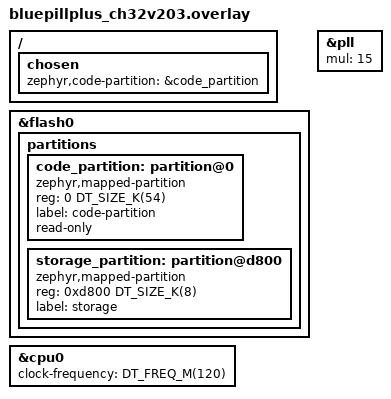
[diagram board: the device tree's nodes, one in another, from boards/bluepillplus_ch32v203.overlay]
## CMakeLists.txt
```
# SPDX-License-Identifier: Apache-2.0

cmake_minimum_required(VERSION 3.28.0)
find_package(Zephyr REQUIRED HINTS $ENV{ZEPHYR_BASE})
project(flash_shell)

FILE(GLOB app_sources src/*.c)
target_sources(app PRIVATE ${app_sources})
```

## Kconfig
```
# Copyright (c) 2020, Linaro Ltd.
# SPDX-License-Identifier: Apache-2.0

source "Kconfig.zephyr"

if ARM_MPU
config MPU_ALLOW_FLASH_WRITE
	def_bool y
endif
```

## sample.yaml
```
sample:
  description: Shell commands for inspecting flash driver behavior
  name: Flash shell
tests:
  sample.drivers.flash.shell:
    tags:
      - flash
      - shell
    filter: CONFIG_FLASH_HAS_DRIVER_ENABLED and dt_chosen_enabled('zephyr,flash-controller')
            and not CONFIG_SOC_SERIES_BSIM_NRFXX
    platform_exclude:
      - stm32h7s78_dk
      - gd32f350r_eval
      - lp_em_cc2340r5moda
    harness: shell
    extra_configs:
      - arch:posix:CONFIG_UART_NATIVE_PTY_0_ON_STDINOUT=y
    min_ram: 12
    integration_platforms:
      - qemu_x86
      - native_sim
```

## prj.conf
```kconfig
CONFIG_PRINTK=y
CONFIG_SHELL=y
CONFIG_LOG=y
CONFIG_FLASH=y
CONFIG_FLASH_SHELL=y
CONFIG_FLASH_SHELL_TEST_COMMANDS=y
CONFIG_FLASH_STM32WBA_BYTE_WRITE_EMULATION=n
```

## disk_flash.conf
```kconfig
# RAM-Disk config
CONFIG_DISK_ACCESS=y
CONFIG_DISK_DRIVERS=y
CONFIG_DISK_DRIVER_RAM=y

# Initialize flash_disk after ramdisk
CONFIG_FLASH_INIT_PRIORITY=51
```

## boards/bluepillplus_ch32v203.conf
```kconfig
CONFIG_USE_DT_CODE_PARTITION=y

# Shrink the defaults to fit within the 52 KiB of flash and 20 KiB of RAM.
CONFIG_FLASH_SHELL_TEST_COMMANDS=n
CONFIG_KERNEL_SHELL=n
CONFIG_DATE_SHELL=n
CONFIG_LOG_MODE_MINIMAL=y
```

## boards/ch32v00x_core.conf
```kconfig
CONFIG_USE_DT_CODE_PARTITION=y

# Shrink the defaults to fit within the 52 KiB of flash and 8 KiB of RAM.
CONFIG_FLASH_SHELL_TEST_COMMANDS=n
CONFIG_FLASH_SHELL_BUFFER_SIZE=0x400
CONFIG_MAIN_STACK_SIZE=440
CONFIG_ISR_STACK_SIZE=256
CONFIG_LOG_MODE_MINIMAL=y
CONFIG_KERNEL_SHELL=n
CONFIG_DATE_SHELL=n
```

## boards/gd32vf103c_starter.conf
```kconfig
# This board only has 32KB SRAM, can not afford 16 KB memory pool, use 8KB instead.
CONFIG_HEAP_MEM_POOL_SIZE=8192
```

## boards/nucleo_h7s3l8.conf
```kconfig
# Copyright (c) 2026 EXALT Technologies
# SPDX-License-Identifier: Apache-2.0

CONFIG_MSPI=y
CONFIG_LOG=n
CONFIG_HEAP_MEM_POOL_SIZE=8192
CONFIG_CACHE_MANAGEMENT=n
CONFIG_SHELL_MINIMAL=y
CONFIG_SIZE_OPTIMIZATIONS=y
```

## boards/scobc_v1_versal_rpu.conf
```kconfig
# SPDX-License-Identifier: Apache-2.0

CONFIG_XIP=n

# Keep the vector table at 0x00000000 (TCM)
CONFIG_ROMSTART_RELOCATION_ROM=y
CONFIG_ROMSTART_REGION_ADDRESS=0x00000000
CONFIG_ROMSTART_REGION_SIZE=1
```

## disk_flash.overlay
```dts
/*
 * Copyright (c) 2023 Endress+Hauser AG
 *
 * SPDX-License-Identifier: Apache-2.0
 */

/ {
	ramdisk0 {
		compatible = "zephyr,ram-disk";
		disk-name = "DISK0";
		sector-size = <512>;
		sector-count = <2>;
	};

	disk_flash: disk_flash {
		compatible = "zephyr,disk-flash";
		status = "okay";
		size = <4096>;
		page-size = <1024>;
		disk-name = "DISK0";
		disk-sector-size = <512>;
		disk-offset = <512>;
	};
};
```

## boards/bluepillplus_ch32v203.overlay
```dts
/*
 * SPDX-FileCopyrightText: Copyright Michael Hope <michaelh@juju.nz>
 *
 * SPDX-License-Identifier: Apache-2.0
 */

/ {
	chosen {
		zephyr,code-partition = &code_partition;
	};
};

&flash0 {
	partitions {
		ranges;
		#address-cells = <1>;
		#size-cells = <1>;

		code_partition: partition@0 {
			compatible = "zephyr,mapped-partition";
			reg = <0 DT_SIZE_K(54)>;
			label = "code-partition";
			read-only;
		};

		storage_partition: partition@d800 {
			compatible = "zephyr,mapped-partition";
			reg = <0xd800 DT_SIZE_K(8)>;
			label = "storage";
		};
	};
};

/*
 * Section 32.1 note 2 says "it is strongly recommended that the system
 * main frequency is not greater than 120M."
 */
&pll {
	mul = <15>;
};

&cpu0 {
	clock-frequency = <DT_FREQ_M(120)>;
};
```

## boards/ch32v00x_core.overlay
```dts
/*
 * SPDX-FileCopyrightText: Copyright Michael Hope <michaelh@juju.nz>
 *
 * SPDX-License-Identifier: Apache-2.0
 */

/ {
	chosen {
		zephyr,code-partition = &code_partition;
	};
};

&flash0 {
	partitions {
		ranges;
		#address-cells = <1>;
		#size-cells = <1>;

		code_partition: partition@0 {
			compatible = "zephyr,mapped-partition";
			reg = <0 DT_SIZE_K(54)>;
			label = "code-partition";
			read-only;
		};

		storage_partition: partition@d800 {
			compatible = "zephyr,mapped-partition";
			reg = <0xd800 DT_SIZE_K(8)>;
			label = "storage";
		};
	};
};
```

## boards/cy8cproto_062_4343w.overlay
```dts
/*
 * SPDX-FileCopyrightText: Copyright (c) 2025 Infineon Technologies AG,
 * or an affiliate of Infineon Technologies AG.
 *
 * SPDX-License-Identifier: Apache-2.0
 */

&flash0 {
	partitions {
		#address-cells = <1>;
		#size-cells = <1>;
		compatible = "fixed-partitions";

		/* Set 3Kb of storage at the end of the of 2Mb flash 0 */
		storage_partition: partition@1ff400 {
			label = "storage";
			reg = <0x1ff400 DT_SIZE_K(3)>;
		};
	};
};
```

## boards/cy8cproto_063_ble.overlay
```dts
/*
 * SPDX-FileCopyrightText: <text>Copyright (c) 2026 Infineon Technologies AG,
 * or an affiliate of Infineon Technologies AG. All rights reserved.</text>
 *
 * SPDX-License-Identifier: Apache-2.0
 */

&flash0 {
	partitions {
		#address-cells = <1>;
		#size-cells = <1>;
		compatible = "fixed-partitions";

		/* Set 3Kb of storage at the end of the of 1Mb flash 0 */
		storage_partition: partition@ff400 {
			label = "storage";
			reg = <0xff400 DT_SIZE_K(3)>;
		};
	};
};
```

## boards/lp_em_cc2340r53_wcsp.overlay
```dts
/*
 * Copyright (c) 2026 Texas Instruments Incorporated
 *
 * SPDX-License-Identifier: Apache-2.0
 */

&spi0 {
	status = "okay";
};
```

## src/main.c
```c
/*
 * Copyright (c) 2017 Linaro Limited
 *
 * SPDX-License-Identifier: Apache-2.0
 */

#include <stdio.h>

int main(void)
{
	printf("Flash shell sample");

	return 0;
}
```
